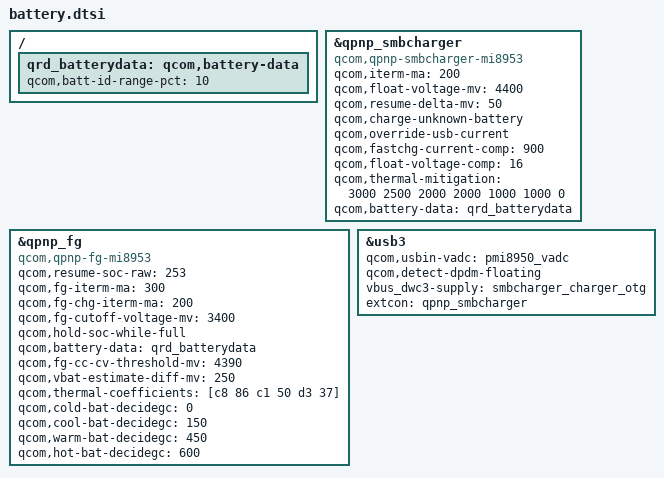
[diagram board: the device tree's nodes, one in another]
/ {
	qrd_batterydata: qcom,battery-data {
		qcom,batt-id-range-pct = <10>;
		#include "../common/batterydata/Sakura-FMT-4v4-4000mah-41kohm.dtsi"
		#include "../common/batterydata/Sakura-GY-4000mah-51kohm.dtsi"
		#include "../common/batterydata/Sakura-XWD-4000mah-78kohm.dtsi"
		#include "../common/batterydata/Sakura-Default-4000mah-41kohm.dtsi"
		/delete-node/ qcom,qrd_msm8937_sku1_2920mah;
	};
};

&qpnp_smbcharger {
	compatible = "qcom,qpnp-smbcharger-mi8953";

	qcom,iterm-ma = <200>;
	qcom,float-voltage-mv = <4400>;
	qcom,resume-delta-mv = <50>;
	qcom,charge-unknown-battery;
	/delete-property/ qcom,parallel-usb-min-current-ma;
	/delete-property/ qcom,parallel-usb-9v-min-current-ma;
	/delete-property/ qcom,parallel-allowed-lowering-ma;
	qcom,override-usb-current;
	qcom,fastchg-current-comp = <900>;
	qcom,float-voltage-comp = <16>;
	/delete-property/ qcom,autoadjust-vfloat;
	/delete-property/ qcom,chg-led-sw-controls;
	/delete-property/ qcom,chg-led-support;
	/delete-property/ qcom,external-typec;
	/delete-property/ qcom,typec-psy-name;
	qcom,thermal-mitigation = <3000 2500 2000 2000 1000 1000 0>;
	qcom,battery-data = <&qrd_batterydata>;
	status = "okay";
};

&qpnp_fg {
	compatible = "qcom,qpnp-fg-mi8953";

	/delete-property/ qcom,resume-soc;
	qcom,resume-soc-raw = <253>;
	qcom,fg-iterm-ma = <300>;
	qcom,fg-chg-iterm-ma = <200>;
	qcom,fg-cutoff-voltage-mv = <3400>;
	qcom,hold-soc-while-full;
	qcom,battery-data = <&qrd_batterydata>;
	qcom,fg-cc-cv-threshold-mv =<4390>;
	qcom,vbat-estimate-diff-mv = <250>;
	qcom,thermal-coefficients = [c8 86 c1 50 d3 37];
	qcom,cold-bat-decidegc = <0>;
	qcom,cool-bat-decidegc = <150>;
	qcom,warm-bat-decidegc = <450>;
	qcom,hot-bat-decidegc = <600>;
	status = "okay";
};

&usb3 {
	qcom,usbin-vadc = <&pmi8950_vadc>;
	qcom,detect-dpdm-floating;
	vbus_dwc3-supply = <&smbcharger_charger_otg>;
	extcon = <&qpnp_smbcharger>;
};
